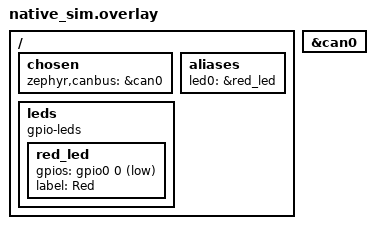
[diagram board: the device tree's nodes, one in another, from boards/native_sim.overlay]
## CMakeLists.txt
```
# SPDX-FileCopyrightText: Copyright (C) Frickly Systems GmbH
# SPDX-FileCopyrightText: Copyright (C) MBition GmbH
#
# SPDX-License-Identifier: Apache-2.0

cmake_minimum_required(VERSION 3.13.1)

find_package(Zephyr REQUIRED HINTS $ENV{ZEPHYR_BASE})
project(uds)

file(GLOB SRC_FILES src/*.c)
target_sources(app PRIVATE ${SRC_FILES})
```

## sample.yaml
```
# Copyright (C) Frickly Systems GmbH
# Copyright (C) MBition GmbH
#
# SPDX-License-Identifier: Apache-2.0

sample:
  name: uds example
common:
  build_only: true
  integration_platforms:
    - ardep
    # this does not work
    # - native_sim/native/64
    # - native_sim
tests:
  example.uds.default:
    sysbuild: true
```

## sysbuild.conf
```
SB_CONFIG_BOOT_LOGIC_UDS_FIRMWARE_LOADER=y
```

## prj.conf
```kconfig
CONFIG_CAN=y

CONFIG_UDS=y

CONFIG_LOG=y
CONFIG_LOG_INFO_COLOR_GREEN=y

CONFIG_HEAP_MEM_POOL_SIZE=1024
CONFIG_STD_C17=y

CONFIG_GPIO=y

# used for generating a seed for the security access function
CONFIG_TEST_RANDOM_GENERATOR=y 

# Enable filesystem support for UDS file transfer tests
CONFIG_FILE_SYSTEM=y
CONFIG_FILE_SYSTEM_LITTLEFS=y
CONFIG_FLASH_MAP=y
CONFIG_FLASH_PAGE_LAYOUT=y

# Enable mbedTLS for cryptographic functions in the  UDS authentication function
CONFIG_MBEDTLS=y
CONFIG_MBEDTLS_BUILTIN=y
# PSA Crypto API provider (authentication.c uses psa_* directly; the legacy
# mbedtls_aes_*/ctr_drbg_*/entropy_* API was removed from the public surface
# in Mbed TLS 4.x)
CONFIG_MBEDTLS_PSA_CRYPTO_C=y
# AES-128 ECB used by aes_encrypt_ecb()/aes_decrypt_ecb()
CONFIG_PSA_WANT_KEY_TYPE_AES=y
CONFIG_PSA_WANT_ALG_ECB_NO_PADDING=y
# DRBG + entropy back the PSA RNG used by psa_generate_random()
CONFIG_MBEDTLS_CTR_DRBG_C=y
CONFIG_MBEDTLS_ENTROPY_C=y

# mbedtls needs more stack
CONFIG_ISO14229_THREAD_STACK_SIZE=4096
```

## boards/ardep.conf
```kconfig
CONFIG_UDS_USE_LINK_CONTROL=y
```

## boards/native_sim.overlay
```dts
/*
 * SPDX-FileCopyrightText: Copyright (C) Frickly Systems GmbH
 * SPDX-FileCopyrightText: Copyright (C) MBition GmbH
 *
 * SPDX-License-Identifier: Apache-2.0
 */

/ {
    chosen {
        zephyr,canbus = &can0;
    };

    aliases {
		led0 = &red_led;
    };

	leds {
		compatible = "gpio-leds";

		red_led: red_led {
            gpios = <&gpio0 0 GPIO_ACTIVE_LOW>;
			label = "Red";
		};
	};
};

&can0 {
    status = "okay";
};
```

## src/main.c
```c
/*
 * SPDX-FileCopyrightText: Copyright (C) Frickly Systems GmbH
 * SPDX-FileCopyrightText: Copyright (C) MBition GmbH
 *
 * SPDX-License-Identifier: Apache-2.0
 */

#include <zephyr/logging/log.h>
LOG_MODULE_REGISTER(uds_sample, LOG_LEVEL_DBG);

#include "uds.h"

#include <zephyr/drivers/can.h>
#include <zephyr/kernel.h>

#include <ardep/iso14229.h>
#include <ardep/uds.h>

static const struct device *can_dev = DEVICE_DT_GET(DT_CHOSEN(zephyr_canbus));

struct uds_instance_t instance;

UDS_REGISTER_ECU_DEFAULT_HARD_RESET_HANDLER(&instance);

int mount_fs(void) { return 0; }

int main(void) {
  int err;
  LOG_INF("ARDEP UDS Sample");

  err = mount_fs();
  if (err) {
    LOG_ERR("Failed to mount filesystem: %d", err);
    return err;
  }

  UDSISOTpCConfig_t cfg = {
    // Hardware Addresses
    .source_addr = 0x7E8,
    .target_addr = 0x7E0,

    // Functional Addresses
    .source_addr_func = 0x7DF,
    .target_addr_func = UDS_TP_NOOP_ADDR,
  };

  uds_init(&instance, &cfg, can_dev, &auth_data);

  if (!device_is_ready(can_dev)) {
    LOG_INF("CAN device not ready");
    return -ENODEV;
  }

  err = can_set_mode(can_dev, CAN_MODE_NORMAL);
  if (err) {
    LOG_ERR("Failed to set CAN mode: %d", err);
    return err;
  }

  err = can_start(can_dev);
  if (err) {
    LOG_ERR(
        "Failed to start CAN device: "
        "%d",
        err);
    return err;
  }
  LOG_INF("CAN device started");

  instance.iso14229.thread_start(&instance.iso14229);
  LOG_INF("UDS thread started");
}

#ifdef CONFIG_UDS_USE_LINK_CONTROL

UDS_REGISTER_LINK_CONTROL_DEFAULT_HANDLER(&instance);

#endif  // CONFIG_UDS_USE_LINK_CONTROL
```

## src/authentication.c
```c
/*
 * SPDX-FileCopyrightText: Copyright (C) Frickly Systems GmbH
 * SPDX-FileCopyrightText: Copyright (C) MBition GmbH
 *
 * SPDX-License-Identifier: Apache-2.0
 */

#include <zephyr/logging/log.h>
LOG_MODULE_DECLARE(uds_sample, LOG_LEVEL_DBG);

#include "iso14229.h"
#include "uds.h"

#include <zephyr/kernel.h>

#include <ardep/uds.h>
#include <psa/crypto.h>

const unsigned char uds_aes_key_bin[] = {0xc3, 0x6a, 0xd3, 0x5c, 0xa2, 0xb7,
                                         0x0e, 0x82, 0xf7, 0xc3, 0x7a, 0xfa,
                                         0x62, 0xad, 0xae, 0xc2};
static const unsigned char *const uds_aes_key = uds_aes_key_bin;

struct authentication_data auth_data = {
  // Whether we are authenticated or not
  .authenticated = false,
  // Current seed we send to the client
  .seeed = {0},
  // BER encoded OID for AES-128 CBC (OID 2.16.840.1.101.3.4.1.2)
  // https://oidref.com/2.16.840.1.101.3.4.1.2
  .algorithm_authenticator = {0x06, 0x09, 0x60, 0x86, 0x48, 0x01, 0x65, 0x03,
                              0x04, 0x01, 0x02, 0x00, 0x00, 0x00, 0x00, 0x00},
};

// AES-128 single-block ECB via the PSA Crypto API. The legacy mbedtls_aes_*
// low-level API was removed from the public surface in Mbed TLS 4.x.
static int aes_ecb_crypt(const uint8_t *key, const uint8_t *input,
                         uint8_t *output, bool encrypt) {
  psa_key_attributes_t attr = PSA_KEY_ATTRIBUTES_INIT;
  psa_key_id_t key_id;
  psa_status_t status;
  size_t output_len;

  if (psa_crypto_init() != PSA_SUCCESS) {
    return -1;
  }

  psa_set_key_usage_flags(
      &attr, encrypt ? PSA_KEY_USAGE_ENCRYPT : PSA_KEY_USAGE_DECRYPT);
  psa_set_key_algorithm(&attr, PSA_ALG_ECB_NO_PADDING);
  psa_set_key_type(&attr, PSA_KEY_TYPE_AES);
  psa_set_key_bits(&attr, 128);

  status = psa_import_key(&attr, key, 16, &key_id);
  if (status != PSA_SUCCESS) {
    return -1;
  }

  if (encrypt) {
    status = psa_cipher_encrypt(key_id, PSA_ALG_ECB_NO_PADDING, input, 16,
                                output, 16, &output_len);
  } else {
    status = psa_cipher_decrypt(key_id, PSA_ALG_ECB_NO_PADDING, input, 16,
                                output, 16, &output_len);
  }

  psa_destroy_key(key_id);

  return (status == PSA_SUCCESS && output_len == 16) ? 0 : -1;
}

int aes_encrypt_ecb(const uint8_t *key, const uint8_t *input, uint8_t *output) {
  return aes_ecb_crypt(key, input, output, true);
}

int aes_decrypt_ecb(const uint8_t *key, const uint8_t *input, uint8_t *output) {
  return aes_ecb_crypt(key, input, output, false);
}

int generate_random_seed(uint8_t *seed) {
  if (psa_crypto_init() != PSA_SUCCESS) {
    return -1;
  }

  return (psa_generate_random(seed, 16) == PSA_SUCCESS) ? 0 : -1;
}

static UDSErr_t auth_check(const struct uds_context *const context,
                           bool *apply_action) {
  *apply_action = true;
  return UDS_OK;
}

static UDSErr_t auth_action(struct uds_context *const context,
                            bool *consume_event) {
  UDSAuthArgs_t *args = context->arg;
  struct authentication_data *auth = context->registration->auth.user_context;

  switch (args->type) {
    case UDS_LEV_AT_RCFA: {  // requestChallengeForAuthentication (0x05)
      LOG_INF("Authentication request received");

      if (memcmp(args->subFuncArgs.reqChallengeArgs.algoInd,
                 auth->algorithm_authenticator, 16) != 0) {
        LOG_ERR("Unsupported algorithm indicator");
        return UDS_NRC_ConditionsNotCorrect;
      }

      if (generate_random_seed(auth->seeed) != 0) {
        LOG_ERR("Failed to generate random seed");
        return UDS_NRC_GeneralReject;
      }

      LOG_HEXDUMP_INF(auth->seeed, 16, "Generated seed");

      uint8_t seed_len[] = {0x00, 0x10};  // 16 bytes
      args->copy(context->server, seed_len, sizeof(seed_len));
      args->copy(context->server, auth->seeed, sizeof(auth->seeed));

      uint8_t additional_param_len[] = {0x00, 0x00};
      args->copy(context->server, additional_param_len,
                 sizeof(additional_param_len));

      return args->set_auth_state(context->server, UDS_AT_RA);
    }
    case UDS_LEV_AT_VPOWNU: {  // verifyProofOfOwnershipUnidirectional (0x06)
      LOG_INF("Verify Proof Of Ownership Unidirectional");

      if (memcmp(args->subFuncArgs.verifyPownArgs.algoInd,
                 auth->algorithm_authenticator, 16) != 0) {
        LOG_ERR("Unsupported algorithm indicator\n");
        return UDS_NRC_ConditionsNotCorrect;
      }

      // Extract proof of ownership (encrypted seed)
      if (args->subFuncArgs.verifyPownArgs.pownLen != 16) {
        LOG_ERR("Invalid proof of ownership length: %d (expected 16)",
                args->subFuncArgs.verifyPownArgs.pownLen);
        return UDS_NRC_IncorrectMessageLengthOrInvalidFormat;
      }

      uint8_t *encrypted_proof =
          (uint8_t *)args->subFuncArgs.verifyPownArgs.pown;
      LOG_HEXDUMP_INF(encrypted_proof, 16, "Received encrypted proof:");

      // Decrypt the proof using our AES key
      uint8_t decrypted_proof[16];
      if (aes_decrypt_ecb(uds_aes_key, encrypted_proof, decrypted_proof) != 0) {
        LOG_ERR("Failed to decrypt proof of ownership");
        return UDS_NRC_GeneralReject;
      }

      LOG_HEXDUMP_INF(decrypted_proof, 16, "Decrypted proof:");
      LOG_HEXDUMP_INF(auth->seeed, 16, "Expected seed:");

      // Compare decrypted proof with the seed we sent
      if (memcmp(decrypted_proof, auth->seeed, 16) != 0) {
        LOG_ERR(
            "Proof verification failed - decrypted proof does not match "
            "seed\n");
        auth->authenticated = false;
        return UDS_NRC_InvalidKey;
      }

      LOG_INF("Proof verification successful! Client is now authenticated.");
      auth->authenticated = true;

      uint8_t session_key_len[] = {0x00, 0x00};
      args->copy(context->server, session_key_len, sizeof(session_key_len));
      return args->set_auth_state(context->server, UDS_AT_OVAC);
    }
    case UDS_LEV_AT_DA: {  // deAuthenticate (0x00)
      LOG_INF("De-authenticate request");
      auth->authenticated = false;

      UDSErr_t ret = args->set_auth_state(context->server, UDS_AT_DAS);
      if (ret != UDS_OK) {
        LOG_INF("Failed to copy de-authentication response");
        return ret;
      }

      return UDS_OK;
    }
    default:
      return UDS_NRC_SubFunctionNotSupported;
  }
}

static UDSErr_t auth_timeout_check(const struct uds_context *const context,
                                   bool *apply_action) {
  *apply_action = true;
  return UDS_OK;
}

static UDSErr_t auth_timeout_action(struct uds_context *const context,
                                    bool *consume_event) {
  struct authentication_data *auth = context->registration->auth.user_context;
  auth->authenticated = false;

  LOG_INF("Authentication timeout - user de-authenticated");

  *consume_event = true;
  return UDS_PositiveResponse;
}

UDS_REGISTER_AUTHENTICATION_HANDLER(&uds_default_instance,
                                    auth_check,
                                    auth_action,
                                    auth_timeout_check,
                                    auth_timeout_action,
                                    &auth_data);
```

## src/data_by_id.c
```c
/*
 * SPDX-FileCopyrightText: Copyright (C) Frickly Systems GmbH
 * SPDX-FileCopyrightText: Copyright (C) MBition GmbH
 *
 * SPDX-License-Identifier: Apache-2.0
 */

#include "iso14229.h"

#include <zephyr/logging/log.h>
LOG_MODULE_DECLARE(uds_sample, LOG_LEVEL_DBG);

#include "uds.h"

#include <zephyr/drivers/gpio.h>
#include <zephyr/kernel.h>
#include <zephyr/sys/byteorder.h>

// Setup data for Data by Identifier handlers
const uint16_t primitive_type_id = 0x50;
uint16_t primitive_type = 5;
uint16_t primitive_type_size = sizeof(primitive_type);

const uint16_t string_id = 0x100;
char string[] = "Hello from UDS";
// Include NULL as string terminator
uint16_t string_size = sizeof(string);

const uint16_t authenticated_type_id = 0x150;
uint8_t authenticated_type = 0x42;
uint16_t authenticated_type_size = sizeof(authenticated_type);

// Check function for the Read Data by Identifier event
// This callback is used for all data identifiers defined above. Because of
// this, we need to check for the dataID in here. Otherwise, we can assume the
// correct data ID because it is checked by the framework
UDSErr_t read_data_by_id_check(const struct uds_context *const context,
                               bool *apply_action) {
  UDSRDBIArgs_t *args = context->arg;

  // Check for authentication if required
  if (args->dataId == authenticated_type_id) {
    struct authentication_data *auth = context->instance->user_context;
    if (!auth->authenticated) {
      LOG_WRN("Access to data id 0x%02X denied - client not authenticated",
              context->registration->data_identifier.data_id);
      // If we are not authenticated, we are not allowed to read this data
      // We return a NRC which gets propagated to the client.
      // No other event handlers are checked after this.
      return UDS_NRC_ConditionsNotCorrect;
    } else {
      LOG_INF("Access to data id 0x%02X granted - client authenticated",
              context->registration->data_identifier.data_id);
    }
  }

  LOG_INF("Check to read data id: 0x%02X successful",
          context->registration->data_identifier.data_id);

  // Set to true, when we want to handle this event
  *apply_action = true;
  return UDS_OK;
}

// Action function for the Read Data by Identifier event
// This callback is used for all data identifiers defined above. Because of
// this, we need to split our actions by dataID.
UDSErr_t read_data_by_id_action(struct uds_context *const context,
                                bool *consume_event) {
  UDSRDBIArgs_t *args = context->arg;

  LOG_INF("Reading data id: 0x%02X", args->dataId);

  uint8_t temp[50] = {0};

  uint16_t size =
      *(uint16_t *)context->registration->data_identifier.user_context;

  if (args->dataId == primitive_type_id) {
    // Convert to MSB-First as defined in the ISO 14229 standard
    uint16_t t = sys_cpu_to_be16(
        *(uint16_t *)context->registration->data_identifier.data);
    memcpy(temp, &t, sizeof(t));
  } else if (args->dataId == string_id ||
             args->dataId == authenticated_type_id) {
    // Transport string or raw data unchanged as raw data without conversion
    memcpy(temp, context->registration->data_identifier.data, size);
  }

  // Signal this action consumes the event
  *consume_event = true;

  // Copy the data into the response buffer
  return args->copy(context->server, temp, size);
}

// Check function for the Write Data by Identifier event
UDSErr_t write_primitive_data_by_id_check(
    const struct uds_context *const context, bool *apply_action) {
  // We don't need any additional checks here, so we can just set `apply_action`
  // and return

  LOG_INF("Check to write data id: 0x%02X successful",
          context->registration->data_identifier.data_id);
  *apply_action = true;
  return UDS_OK;
}

// Write function for the Write Data by Identifier event
UDSErr_t write_primitive_data_by_id_action(struct uds_context *const context,
                                           bool *consume_event) {
  UDSWDBIArgs_t *args = context->arg;

  // Convert the data from BE to CPU order
  uint16_t *data = context->registration->data_identifier.data;
  *data = sys_be16_to_cpu(*(uint16_t *)args->data);

  LOG_INF("Written data to id 0x%02X: 0x%04X",
          context->registration->data_identifier.data_id, *data);

  // Signal this action consumes the event
  *consume_event = true;

  return UDS_PositiveResponse;
}

// Register the data identifiers defined above
UDS_REGISTER_DATA_BY_IDENTIFIER_HANDLER(
    // UDS instance the event handler is registered for
    &instance,
    // Data Identifier of the data
    primitive_type_id,
    // Pointer to the data
    &primitive_type,
    // check and action functions to read and write the data
    read_data_by_id_check,
    read_data_by_id_action,
    write_primitive_data_by_id_check,
    write_primitive_data_by_id_action,
    // IO Control check and action functions (unsused and therefore set to NULL)
    NULL,
    NULL,
    // User context pointer (used to store the size of the data here)
    &primitive_type_size);

UDS_REGISTER_DATA_BY_IDENTIFIER_HANDLER(&instance,
                                        string_id,
                                        &string,
                                        read_data_by_id_check,
                                        read_data_by_id_action,
                                        NULL,
                                        NULL,
                                        NULL,
                                        NULL,
                                        &string_size);

UDS_REGISTER_DATA_BY_IDENTIFIER_HANDLER(&instance,
                                        authenticated_type_id,
                                        &authenticated_type,
                                        read_data_by_id_check,
                                        read_data_by_id_action,
                                        NULL,
                                        NULL,
                                        NULL,
                                        NULL,
                                        &authenticated_type_size);

#define LED0_NODE DT_ALIAS(led0)

static const struct gpio_dt_spec led = GPIO_DT_SPEC_GET(LED0_NODE, gpios);

K_MUTEX_DEFINE(led_data_mutex);

const uint16_t led_id = 0x200;
struct {
  // LED state as set by the WriteDataByIdentifier service
  uint8_t led_state;
  // LED state override from io_control
  uint8_t io_control_led_state;
  // Whether IO Control is active or not
  bool io_control_active;
} led_data;

UDSErr_t read_led_check(const struct uds_context *const context,
                        bool *apply_action) {
  // We don't need any additional checks here, so we can just set `apply_action`
  // and return

  LOG_INF("Check to read led state");
  *apply_action = true;
  return UDS_OK;
}

UDSErr_t read_led_action(struct uds_context *const context,
                         bool *consume_event) {
  int led_state = gpio_pin_get_dt(&led);
  if (led_state < 0) {
    LOG_ERR("Failed to read LED state");
    // Return an error if something goes wrong during the handling of the event
    return UDS_NRC_ConditionsNotCorrect;
  }
  LOG_INF("Reading led state: 0x%02X", led_state);

  UDSRDBIArgs_t *args = context->arg;
  uint8_t state = (uint8_t)led_state;

  *consume_event = true;
  return args->copy(context->server, &state, sizeof(state));
}

UDSErr_t write_led_check(const struct uds_context *const context,
                         bool *apply_action) {
  // We don't need any additional checks here, so we can just set `apply_action`
  // and return

  LOG_INF("Check to update led state");
  *apply_action = true;
  return UDS_OK;
}

UDSErr_t write_led_action(struct uds_context *const context,
                          bool *consume_event) {
  UDSWDBIArgs_t *args = context->arg;
  if (args->len < 1) {
    LOG_ERR("Invalid data length for LED state");
    return UDS_NRC_IncorrectMessageLengthOrInvalidFormat;
  }

  uint8_t new_led_state = args->data[0];

  k_mutex_lock(&led_data_mutex, K_FOREVER);
  // We set the led state here, but it will not get applied if we disabled
  // updates via IOControl
  led_data.led_state = new_led_state;
  k_mutex_unlock(&led_data_mutex);

  LOG_INF("Updated LED state: 0x%02X", new_led_state);
  *consume_event = true;

  return UDS_PositiveResponse;
}

UDSErr_t io_ctrl_led_check(const struct uds_context *const context,
                           bool *apply_action) {
  LOG_INF("Check for LED IO control");
  *apply_action = true;
  return UDS_OK;
}

UDSErr_t io_ctrl_led_action(struct uds_context *const context,
                            bool *consume_event) {
  UDSIOCtrlArgs_t *args = context->arg;

  if (args->ioCtrlParam == UDS_IO_CONTROL__SHORT_TERM_ADJUSTMENT &&
      args->ctrlStateAndMaskLen >= 1) {
    k_mutex_lock(&led_data_mutex, K_FOREVER);
    int current_led_state = gpio_pin_get_dt(&led);
    if (current_led_state < 0) {
      k_mutex_unlock(&led_data_mutex);
      LOG_ERR("Failed to read LED state (IO control)");
      return UDS_NRC_ConditionsNotCorrect;
    }

    // Set IO Control active to notify the update thread to not apply received
    // updates anymore
    led_data.io_control_active = true;
    led_data.io_control_led_state = *(uint8_t *)args->ctrlStateAndMask;
    LOG_INF("Set LED state (IO control): 0x%02X",
            led_data.io_control_led_state);
    k_mutex_unlock(&led_data_mutex);

    uint8_t state = (uint8_t)current_led_state;
    return args->copy(context->server, &state, sizeof(state));
  } else if (args->ioCtrlParam == UDS_IO_CONTROL__RESET_TO_DEFAULT) {
    k_mutex_lock(&led_data_mutex, K_FOREVER);
    const uint8_t state = 0;
    // Reset to the default state (0) for both, 'actual' value and IO Control
    // override
    led_data.io_control_led_state = state;
    led_data.led_state = state;
    k_mutex_unlock(&led_data_mutex);

    return args->copy(context->server, &state, sizeof(state));
  }
  if (args->ioCtrlParam == UDS_IO_CONTROL__RETURN_CONTROL_TO_ECU) {
    k_mutex_lock(&led_data_mutex, K_FOREVER);
    // Disable IO Control, so that the update thread applies the last set
    // led_state again
    uint8_t state = led_data.led_state;
    led_data.io_control_active = false;
    k_mutex_unlock(&led_data_mutex);

    return args->copy(context->server, &state, sizeof(state));
  }

  return UDS_NRC_RequestOutOfRange;
}

UDS_REGISTER_DATA_BY_IDENTIFIER_HANDLER(&instance,
                                        led_id,
                                        &led_data.led_state,
                                        read_led_check,
                                        read_led_action,
                                        write_led_check,
                                        write_led_action,
                                        io_ctrl_led_check,
                                        io_ctrl_led_action,
                                        &led_data);

// Thread that periodically updates the LED state depending on the state and
// the override from IO Control
void led_update_thread(void *p1, void *p2, void *p3) {
  ARG_UNUSED(p1);
  ARG_UNUSED(p2);
  ARG_UNUSED(p3);

  k_mutex_lock(&led_data_mutex, K_FOREVER);
  int ret = gpio_pin_configure_dt(&led, GPIO_OUTPUT_ACTIVE);
  if (ret < 0) {
    LOG_ERR("Unable to configure led\n");
    return;
  }

  led_data.led_state = 0;
  led_data.io_control_active = false;
  led_data.io_control_led_state = 0;
  k_mutex_unlock(&led_data_mutex);

  while (true) {
    k_mutex_lock(&led_data_mutex, K_FOREVER);
    // If IO Control is active, we want to set the override state
    if (led_data.io_control_active) {
      gpio_pin_set_dt(&led, led_data.io_control_led_state);
    } else {
      gpio_pin_set_dt(&led, led_data.led_state);
    }
    k_mutex_unlock(&led_data_mutex);
    k_sleep(K_MSEC(100));
  }
}

K_THREAD_DEFINE(led_update_thread_id,
                512,
                led_update_thread,
                NULL,
                NULL,
                NULL,
                K_PRIO_PREEMPT(7),
                0,
                0);
```

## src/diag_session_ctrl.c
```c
/*
 * SPDX-FileCopyrightText: Copyright (C) Frickly Systems GmbH
 * SPDX-FileCopyrightText: Copyright (C) MBition GmbH
 *
 * SPDX-License-Identifier: Apache-2.0
 */

#include <zephyr/logging/log.h>
LOG_MODULE_DECLARE(uds_sample, LOG_LEVEL_DBG);

#include "uds.h"

#include <zephyr/retention/bootmode.h>
#include <zephyr/retention/retention.h>
#include <zephyr/sys/reboot.h>

#include <ardep/uds.h>

const struct device* retention_data =
    DEVICE_DT_GET(DT_CHOSEN(zephyr_firmware_loader_args));

// Check function for the Diagnostic Session Control event
UDSErr_t diag_session_ctrl_check(const struct uds_context* const context,
                                 bool* apply_action) {
  // Type the argument object
  // We don't need to check, that the event matches. This is done internally by
  // the UDS lib
  UDSDiagSessCtrlArgs_t* args = context->arg;

  // Set to true, if the action should be applied.
  // Here you can check other conditions if needed
  *apply_action = true;
  LOG_INF("Check to change diagnostic session to 0x%02X successful",
          args->type);

  // Return `UDS_OK` if everything is fine, or an NRC to abort event handling
  // and return this error code to the client
  return UDS_OK;
}

// Action function for the Diagnostic Session Control event
UDSErr_t diag_session_ctrl_action(struct uds_context* const context,
                                  bool* consume_event) {
  UDSDiagSessCtrlArgs_t* args = context->arg;

  if (args->type == UDS_DIAG_SESSION__PROGRAMMING) {
    LOG_INF("Switching into firmware loader");
    return uds_switch_to_firmware_loader_with_programming_session();
  }

  LOG_INF("Changing diagnostic session to 0x%02X", args->type);

  // We don't want to consume the event here, because the LinkControl handler
  // must know about it so it can reset the bitrate to its default value
  // If there are no other event handlers that would need the event, you can
  // stop iteration over other event handlers by setting `*consume_event =
  // true;`
  *consume_event = false;

  // Return the response code that the service should return to the client
  return UDS_PositiveResponse;
}

// Check function for the Diagnostic Session Timeout event
// This event is generated independent of the client and emitted when the
// Session timeout is reached
UDSErr_t diag_session_timeout_check(const struct uds_context* const context,
                                    bool* apply_action) {
  *apply_action = true;
  LOG_INF("Check to act on Diagnostic Session Timeout successful");
  return UDS_OK;
}

// Action function for the Diagnostic Session Timeout event
UDSErr_t diag_session_timeout_action(struct uds_context* const context,
                                     bool* consume_event) {
  LOG_INF("Diagnostic Session Timeout handled");

  // We don't want to consume the event here, because the LinkControl handler
  // must know about it so it can reset the bitrate to its default value
  *consume_event = false;

  // As this is not tied to a client request, nothing will be returned to the
  // client. This just signals the unterlying server whether the event was
  // handled successfully.
  return UDS_PositiveResponse;
}

// Registration Macro to register the event handlers we defined above
UDS_REGISTER_DIAG_SESSION_CTRL_HANDLER(
    // The UDS instance we want to register
    // the handler for
    &instance,
    // Check and Action functions for the events
    diag_session_ctrl_check,
    diag_session_ctrl_action,
    diag_session_timeout_check,
    diag_session_timeout_action,
    // Optional user context pointer that is passed wit the context to every
    // handler
    NULL)
```

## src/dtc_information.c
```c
/*
 * SPDX-FileCopyrightText: Copyright (C) Frickly Systems GmbH
 * SPDX-FileCopyrightText: Copyright (C) MBition GmbH
 *
 * SPDX-License-Identifier: Apache-2.0
 */

#include <zephyr/logging/log.h>
LOG_MODULE_DECLARE(uds_sample, LOG_LEVEL_DBG);

#include "ardep/iso14229.h"
#include "ardep/uds.h"
#include "uds.h"

#include <zephyr/kernel.h>

K_MUTEX_DEFINE(dtc_record_mutex);

struct DtcRecord {
  uint8_t dtc[3];
  uint8_t status;
  bool is_active;
  bool is_frozen;
};

const uint8_t dtc_status_availability_mask = 0x7F;
struct DtcRecord dtc_records[] = {
  {.dtc = {0x0A, 0x9B, 0x17},
   .status = 0x24,
   .is_active = true,
   .is_frozen = false},
  {.dtc = {0x80, 0x51, 0x11},
   .status = 0x2F,
   .is_active = true,
   .is_frozen = false},
};

UDSErr_t read_dtc_info_check(const struct uds_context *const context,
                             bool *apply_action) {
  UDSRDTCIArgs_t *args = context->arg;

  // We don't need to filter/check the subfunction ID as this is checked
  // internally before calling this function.

  LOG_INF("Reading DT information by status mask: 0x%02X",
          args->subFuncArgs.numOfDTCByStatusMaskArgs.mask);

  *apply_action = true;
  return UDS_OK;
}

UDSErr_t read_dtc_info_action(struct uds_context *const context,
                              bool *consume_event) {
  UDSRDTCIArgs_t *args = context->arg;

  int ret = args->copy(context->server, &dtc_status_availability_mask,
                       sizeof(dtc_status_availability_mask));
  if (ret != UDS_OK) {
    LOG_ERR("Failed to copy DTC status availability mask: %d", ret);
    return ret;
  }

  k_mutex_lock(&dtc_record_mutex, K_FOREVER);
  for (uint32_t i = 0; i < ARRAY_SIZE(dtc_records); i++) {
    if (dtc_records[i].status &
            args->subFuncArgs.numOfDTCByStatusMaskArgs.mask &&
        dtc_records[i].is_active) {
      ret = args->copy(context->server, dtc_records[i].dtc,
                       sizeof(dtc_records[i].dtc));
      if (ret != UDS_OK) {
        uint32_t dtc_value = (dtc_records[i].dtc[0] << 16) |
                             (dtc_records[i].dtc[1] << 8) |
                             dtc_records[i].dtc[2];
        LOG_ERR("Failed to copy DTC: 0x%06X ; Err = %d", dtc_value, ret);
        k_mutex_unlock(&dtc_record_mutex);
        return ret;
      }
      ret = args->copy(context->server, &dtc_records[i].status,
                       sizeof(dtc_records[i].status));
      if (ret != UDS_OK) {
        uint32_t dtc_value = (dtc_records[i].dtc[0] << 16) |
                             (dtc_records[i].dtc[1] << 8) |
                             dtc_records[i].dtc[2];
        LOG_ERR("Failed to copy DTC status: 0x%06X (status: 0x%02X) ; Err = %d",
                dtc_value, dtc_records[i].status, ret);
        k_mutex_unlock(&dtc_record_mutex);
        return ret;
      }
    }
  }

  k_mutex_unlock(&dtc_record_mutex);

  *consume_event = true;
  return UDS_PositiveResponse;
}

UDS_REGISTER_READ_DTC_INFO_HANDLER(
    &instance,
    read_dtc_info_check,
    read_dtc_info_action,
    UDS_READ_DTC_INFO_SUBFUNC__DTC_BY_STATUS_MASK,
    NULL)

static void dtc_reactivate_work_handler(struct k_work *work) {
  k_mutex_lock(&dtc_record_mutex, K_FOREVER);
  for (uint32_t i = 0; i < ARRAY_SIZE(dtc_records); i++) {
    dtc_records[i].is_active = true;
  }
  k_mutex_unlock(&dtc_record_mutex);

  LOG_DBG("DTCs reactivated after clear operation");
}

K_WORK_DELAYABLE_DEFINE(dtc_reactivate_work, dtc_reactivate_work_handler);

UDSErr_t clear_diag_info_check(const struct uds_context *const context,
                               bool *apply_action) {
  UDSCDIArgs_t *args = context->arg;

  LOG_INF("Clearing Diagnostic information with group of DTC: 0x%06X",
          args->groupOfDTC);

  *apply_action = true;
  return UDS_OK;
}

UDSErr_t clear_diag_info_act(struct uds_context *const context,
                             bool *consume_event) {
  k_mutex_lock(&dtc_record_mutex, K_FOREVER);
  for (uint32_t i = 0; i < ARRAY_SIZE(dtc_records); i++) {
    dtc_records[i].is_active = false;
  }
  k_mutex_unlock(&dtc_record_mutex);

  // Schedule work to reactivate DTCs after 1 second
  if (k_work_delayable_is_pending(&dtc_reactivate_work)) {
    k_work_cancel_delayable(&dtc_reactivate_work);
  }
  k_work_schedule(&dtc_reactivate_work, K_SECONDS(1));

  *consume_event = true;
  return UDS_PositiveResponse;
}

UDS_REGISTER_CLEAR_DIAG_INFO_HANDLER(&instance,
                                     clear_diag_info_check,
                                     clear_diag_info_act,
                                     NULL)

// Control DTC Setting handlers
UDSErr_t control_dtc_setting_check(const struct uds_context *const context,
                                   bool *apply_action) {
  UDSControlDTCSettingArgs_t *args = context->arg;

  LOG_INF("Control DTC Setting request - Type: 0x%02X, Length: %u", args->type,
          args->len);

  *apply_action = true;
  return UDS_OK;
}

UDSErr_t control_dtc_setting_action(struct uds_context *const context,
                                    bool *consume_event) {
  UDSControlDTCSettingArgs_t *args = context->arg;

  k_mutex_lock(&dtc_record_mutex, K_FOREVER);

  switch (args->type) {
    case 0x01:  // DTCSettingOn - Resume DTC status updates
      LOG_INF("DTC Setting ON - Resuming DTC status updates");
      for (uint32_t i = 0; i < ARRAY_SIZE(dtc_records); i++) {
        dtc_records[i].is_frozen = false;
      }
      break;

    case 0x02:  // DTCSettingOff - Freeze DTC status updates
      LOG_INF("DTC Setting OFF - Freezing DTC status updates");
      for (uint32_t i = 0; i < ARRAY_SIZE(dtc_records); i++) {
        dtc_records[i].is_frozen = true;
      }
      break;

    default:
      k_mutex_unlock(&dtc_record_mutex);
      LOG_WRN("Unsupported DTC Setting type: 0x%02X", args->type);
      *consume_event = false;
      return UDS_NRC_SubFunctionNotSupported;
  }

  k_mutex_unlock(&dtc_record_mutex);

  *consume_event = true;
  return UDS_PositiveResponse;
}

UDS_REGISTER_CONTROL_DTC_SETTING_HANDLER(&instance,
                                         control_dtc_setting_check,
                                         control_dtc_setting_action,
                                         NULL)

// Forward declaration for DTC status increment work
static void dtc_status_increment_work_handler(struct k_work *work);
K_WORK_DELAYABLE_DEFINE(dtc_status_increment_work,
                        dtc_status_increment_work_handler);

// DTC Status increment worker - runs every 50ms
static void dtc_status_increment_work_handler(struct k_work *work) {
  k_mutex_lock(&dtc_record_mutex, K_FOREVER);

  for (uint32_t i = 0; i < ARRAY_SIZE(dtc_records); i++) {
    if (!dtc_records[i].is_frozen) {
      dtc_records[i].status = (dtc_records[i].status + 1) & 0xFF;
    }
  }

  k_mutex_unlock(&dtc_record_mutex);

  // Reschedule for next increment
  k_work_schedule(&dtc_status_increment_work, K_MSEC(50));
}

// Initialize the DTC status increment worker
static int dtc_status_init(void) {
  LOG_INF("Starting DTC status increment worker (50ms interval)");
  k_work_schedule(&dtc_status_increment_work, K_MSEC(50));
  return 0;
}

SYS_INIT(dtc_status_init, APPLICATION, CONFIG_APPLICATION_INIT_PRIORITY);
```

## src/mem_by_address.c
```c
/*
 * SPDX-FileCopyrightText: Copyright (C) Frickly Systems GmbH
 * SPDX-FileCopyrightText: Copyright (C) MBition GmbH
 *
 * SPDX-License-Identifier: Apache-2.0
 */

#include <zephyr/logging/log.h>
LOG_MODULE_DECLARE(uds_sample, LOG_LEVEL_DBG);

#include "ardep/uds.h"
#include "iso14229.h"
#include "uds.h"

const uint32_t fake_memory_start_addr = 0x00001000;
uint8_t fake_memory[100] = {
  0x01, 0x02, 0x03, 0x04, 0x05, 0x05, 0x07, 0x08, 0x09, 0x0A, 0x0B, 0x0C, 0x0D,
  0x0E, 0x0F, 0x10, 0x11, 0x12, 0x13, 0x14, 0x15, 0x16, 0x17, 0x18, 0x19, 0x1A,
  0x1B, 0x1C, 0x1D, 0x1E, 0x1F, 0x20, 0x21, 0x22, 0x23, 0x24, 0x25, 0x26, 0x27,
  0x28, 0x29, 0x2A, 0x2B, 0x2C, 0x2D, 0x2E, 0x2F, 0x30, 0x31, 0x32, 0x33, 0x34,
  0x35, 0x36, 0x37, 0x38, 0x39, 0x3A, 0x3B, 0x3C, 0x3D, 0x3E, 0x3F, 0x40, 0x41,
  0x42, 0x43, 0x44, 0x45, 0x46, 0x47, 0x48, 0x49, 0x4A, 0x4B, 0x4C, 0x4D, 0x4E,
  0x4F, 0x50, 0x51, 0x52, 0x53, 0x54, 0x55, 0x56, 0x57, 0x58, 0x59, 0x5A, 0x5B,
  0x5C, 0x5D, 0x5E, 0x5F, 0x60, 0x61, 0x62, 0x63, 0x64};

UDSErr_t read_mem_by_address_check(const struct uds_context *const context,
                                   bool *apply_action) {
  UDSReadMemByAddrArgs_t *args = context->arg;
  uint32_t addr = (uint32_t)(uintptr_t)args->memAddr;
  uint32_t size = args->memSize;

  // Check if the address is within our fake memory range
  if (addr < fake_memory_start_addr ||
      (addr + size) >= (fake_memory_start_addr + sizeof(fake_memory))) {
    return UDS_OK;
  }

  *apply_action = true;
  LOG_INF("Check to read memory at address 0x%08X with size %d successful",
          addr, size);

  *apply_action = true;
  return UDS_OK;
}

UDSErr_t read_mem_by_address_action(struct uds_context *const context,
                                    bool *consume_event) {
  UDSReadMemByAddrArgs_t *args = context->arg;
  uint32_t addr = (uint32_t)(uintptr_t)args->memAddr;
  uint32_t size = args->memSize;

  LOG_INF("Reading memory at address 0x%08X with size %d", addr, size);

  return args->copy(context->server,
                    &fake_memory[addr - fake_memory_start_addr], size);
}

UDSErr_t write_mem_by_address_check(const struct uds_context *const context,
                                    bool *apply_action) {
  UDSWriteMemByAddrArgs_t *args = context->arg;
  uint32_t addr = (uint32_t)(uintptr_t)args->memAddr;
  uint32_t size = args->memSize;

  // Check if the address is within our fake memory range
  if (addr < fake_memory_start_addr ||
      (addr + size) >= (fake_memory_start_addr + sizeof(fake_memory))) {
    return UDS_OK;
  }

  *apply_action = true;
  LOG_INF("Check to write memory at address 0x%08X with size %d successful",
          addr, size);

  *apply_action = true;
  return UDS_OK;
}

UDSErr_t write_mem_by_address_action(struct uds_context *const context,
                                     bool *consume_event) {
  UDSWriteMemByAddrArgs_t *args = context->arg;
  uint32_t addr = (uint32_t)(uintptr_t)args->memAddr;
  uint32_t size = args->memSize;

  LOG_HEXDUMP_INF(args->data, size, "Writing to memory");

  memcpy(&fake_memory[addr - fake_memory_start_addr], args->data, size);

  return UDS_PositiveResponse;
}

UDS_REGISTER_MEMORY_HANDLER(&instance,
                            read_mem_by_address_check,
                            read_mem_by_address_action,
                            write_mem_by_address_check,
                            write_mem_by_address_action,
                            NULL)
```

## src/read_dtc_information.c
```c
/*
 * Copyright (C) Frickly Systems GmbH
 * Copyright (C) MBition GmbH
 *
 * SPDX-License-Identifier: Apache-2.0
 */

#include "ardep/uds.h"
#include "iso14229.h"

#include <zephyr/logging/log.h>
LOG_MODULE_DECLARE(uds_sample, LOG_LEVEL_DBG);

#include "uds.h"

struct DtcRecord {
  uint8_t dtc[3];
  uint8_t status;
};

const uint8_t dtc_status_availability_mask = 0x7F;
const struct DtcRecord dtc_records[] = {
  {.dtc = {0x0A, 0x9B, 0x17}, .status = 0x24},
  {.dtc = {0x80, 0x51, 0x11}, .status = 0x2F},
};

UDSErr_t read_dtc_info_check(const struct uds_context *const context,
                             bool *apply_action) {
  UDSRDTCIArgs_t *args = context->arg;

  // We don't need to filter/chck the subfunction ID as this is checked
  // internally before calling this function.

  LOG_INF("Reading DT information by status mask: 0x%02X",
          args->subFuncArgs.numOfDTCByStatusMaskArgs.mask);

  *apply_action = true;
  return UDS_OK;
}

UDSErr_t read_dtc_info_action(struct uds_context *const context,
                              bool *consume_event) {
  UDSRDTCIArgs_t *args = context->arg;

  int ret = args->copy(&context->instance->iso14229.server,
                       &dtc_status_availability_mask,
                       sizeof(dtc_status_availability_mask));
  if (ret != UDS_OK) {
    LOG_ERR("Failed to copy DTC status availability mask: %d", ret);
    return ret;
  }

  for (uint32_t i = 0; i < ARRAY_SIZE(dtc_records); i++) {
    if (dtc_records[i].status &
        args->subFuncArgs.numOfDTCByStatusMaskArgs.mask) {
      ret = args->copy(&context->instance->iso14229.server, dtc_records[i].dtc,
                       sizeof(dtc_records[i].dtc));
      if (ret != UDS_OK) {
        uint32_t dtc_value = (dtc_records[i].dtc[0] << 16) |
                             (dtc_records[i].dtc[1] << 8) |
                             dtc_records[i].dtc[2];
        LOG_ERR("Failed to copy DTC: 0x%06X ; Err = %d", dtc_value, ret);
        return ret;
      }
      ret = args->copy(&context->instance->iso14229.server,
                       &dtc_records[i].status, sizeof(dtc_records[i].status));
      if (ret != UDS_OK) {
        uint32_t dtc_value = (dtc_records[i].dtc[0] << 16) |
                             (dtc_records[i].dtc[1] << 8) |
                             dtc_records[i].dtc[2];
        LOG_ERR("Failed to copy DTC status: 0x%06X (status: 0x%02X) ; Err = %d",
                dtc_value, dtc_records[i].status, ret);
        return ret;
      }
    }
  }

  *consume_event = true;
  return UDS_PositiveResponse;
}

UDS_REGISTER_READ_DTC_INFO_HANDLER(
    &instance,
    read_dtc_info_check,
    read_dtc_info_action,
    UDS_READ_DTC_INFO_SUBFUNC__DTC_BY_STATUS_MASK,
    NULL)
```

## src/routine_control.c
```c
/*
 * SPDX-FileCopyrightText: Copyright (C) Frickly Systems GmbH
 * SPDX-FileCopyrightText: Copyright (C) MBition GmbH
 *
 * SPDX-License-Identifier: Apache-2.0
 */

#include <zephyr/logging/log.h>
LOG_MODULE_DECLARE(uds_sample, LOG_LEVEL_DBG);

#include "ardep/uds.h"
#include "uds.h"

#include <string.h>

#include <zephyr/kernel.h>
#include <zephyr/sys/byteorder.h>

#define SYNCHRONOUS_ROUTINE_ID 0x1234
#define ASYNCHRONOUS_ROUTINE_ID 0x5678

static UDSErr_t sync_routine_control_check(
    const struct uds_context *const context, bool *apply_action) {
  UDSRoutineCtrlArgs_t *args = context->arg;

  // We don't need to check the routine id, the framework already did that for
  // us

  if (args->len != 4) {
    // we operate on an uint32_t so we check the length of the status record
    return UDS_NRC_IncorrectMessageLengthOrInvalidFormat;
  }

  *apply_action = true;
  return UDS_OK;
}

static uint32_t sync_action(uint32_t input) {
  // Simulate some work
  k_msleep(30);
  return ~input;
}

static UDSErr_t sync_routine_control_action(struct uds_context *const context,
                                            bool *consume_event) {
  UDSRoutineCtrlArgs_t *args = context->arg;
  uint32_t input = sys_be32_to_cpu(*(uint32_t *)args->optionRecord);

  uint32_t output = sys_cpu_to_be32(sync_action(input));

  // Signal this action consumes the event
  *consume_event = true;

  return args->copyStatusRecord(context->server, &output, sizeof(output));
}

UDS_REGISTER_ROUTINE_CONTROL_HANDLER(&instance,
                                     SYNCHRONOUS_ROUTINE_ID,
                                     sync_routine_control_check,
                                     sync_routine_control_action,
                                     NULL)

enum async_work_status {
  ASYNC_WORK_STATUS_IDLE = 0,
  ASYNC_WORK_STATUS_SUCCESS = 1,
  ASYNC_WORK_STATUS_STOPPED = 2,
  ASYNC_WORK_STATUS_RUNNING = 3,
};

struct uds_async_work_data {
  uint32_t current_progress;
  enum async_work_status status;
  bool force_stop;
} async_work_data;

K_MUTEX_DEFINE(async_work_mutex);

void async_action(struct k_work *work) {
  k_mutex_lock(&async_work_mutex, K_FOREVER);
  if (async_work_data.status == ASYNC_WORK_STATUS_RUNNING) {
    // work is already running, so we do nothing
    k_mutex_unlock(&async_work_mutex);
    return;
  }

  async_work_data.status = ASYNC_WORK_STATUS_RUNNING;
  async_work_data.current_progress = 0;
  async_work_data.force_stop = false;
  k_mutex_unlock(&async_work_mutex);

  for (size_t i = 0; i < 3000; i++) {
    // Simulate some work
    k_msleep(1);
    k_mutex_lock(&async_work_mutex, K_FOREVER);
    if (async_work_data.force_stop) {
      async_work_data.status = ASYNC_WORK_STATUS_STOPPED;
      k_mutex_unlock(&async_work_mutex);
      return;
    }
    async_work_data.current_progress += 1;
    k_mutex_unlock(&async_work_mutex);
  }

  k_mutex_lock(&async_work_mutex, K_FOREVER);
  async_work_data.status = ASYNC_WORK_STATUS_SUCCESS;
  k_mutex_unlock(&async_work_mutex);
}

K_WORK_DELAYABLE_DEFINE(async_routine_work, async_action);

struct uds_async_routine_data {
  struct uds_async_work_data *work_data;
  struct k_work_delayable *work;
} async_routine_data = {
  .work_data = &async_work_data,
  .work = &async_routine_work,
};

static UDSErr_t async_routine_control_check(
    const struct uds_context *const context, bool *apply_action) {
  *apply_action = true;
  return UDS_OK;
}

static UDSErr_t async_routine_control_action(struct uds_context *const context,
                                             bool *consume_event) {
  UDSRoutineCtrlArgs_t *args = context->arg;
  struct uds_async_routine_data *data =
      context->registration->routine_control.user_context;

  *consume_event = true;

  switch (args->ctrlType) {
    case UDS_ROUTINE_CONTROL__START_ROUTINE: {
      // Check if work is already running
      if (k_work_delayable_is_pending(data->work)) {
        return UDS_NRC_RequestSequenceError;
      }

      // Check if work is already completed or stopped (should be idle to start)
      k_mutex_lock(&async_work_mutex, K_FOREVER);
      if (data->work_data->status == ASYNC_WORK_STATUS_RUNNING) {
        k_mutex_unlock(&async_work_mutex);
        return UDS_NRC_RequestSequenceError;
      }
      k_mutex_unlock(&async_work_mutex);

      // Schedule the work to start immediately
      int ret = k_work_schedule(data->work, K_NO_WAIT);
      if (ret < 0) {
        LOG_ERR("Failed to schedule async work: %d", ret);
        return UDS_NRC_ConditionsNotCorrect;
      }

      LOG_INF("Started async routine");

      // Return success status for start
      return UDS_PositiveResponse;
    }

    case UDS_ROUTINE_CONTROL__STOP_ROUTINE: {
      k_mutex_lock(&async_work_mutex, K_FOREVER);
      if (data->work_data->status != ASYNC_WORK_STATUS_RUNNING) {
        k_mutex_unlock(&async_work_mutex);
        return UDS_NRC_RequestSequenceError;
      }

      LOG_INF("Stopping async routine");

      // Signal the work to stop
      data->work_data->force_stop = true;
      k_mutex_unlock(&async_work_mutex);

      // Cancel pending work if still scheduled
      k_work_cancel_delayable(data->work);

      // Return stop acknowledgment
      uint8_t stop_status = ASYNC_WORK_STATUS_STOPPED;
      return args->copyStatusRecord(context->server, &stop_status,
                                    sizeof(stop_status));
    }

    case UDS_ROUTINE_CONTROL__REQUEST_ROUTINE_RESULTS: {
      k_mutex_lock(&async_work_mutex, K_FOREVER);
      LOG_INF("Sending async routine result");

      uint8_t output[5] = {0};
      output[0] = data->work_data->status;

      // Include progress data
      uint32_t progress_be = sys_cpu_to_be32(data->work_data->current_progress);
      memcpy(&output[1], &progress_be, sizeof(progress_be));

      k_mutex_unlock(&async_work_mutex);

      return args->copyStatusRecord(context->server, output, sizeof(output));
    }

    default:
      return UDS_NRC_SubFunctionNotSupported;
  }
}

UDS_REGISTER_ROUTINE_CONTROL_HANDLER(&instance,
                                     ASYNCHRONOUS_ROUTINE_ID,
                                     async_routine_control_check,
                                     async_routine_control_action,
                                     &async_routine_data)
```

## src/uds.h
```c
/*
 * SPDX-FileCopyrightText: Copyright (C) Frickly Systems GmbH
 * SPDX-FileCopyrightText: Copyright (C) MBition GmbH
 *
 * SPDX-License-Identifier: Apache-2.0
 */

#ifndef ARDEP_SAMPLES_UDS_SRC_UDS_H
#define ARDEP_SAMPLES_UDS_SRC_UDS_H

#include <ardep/uds.h>

extern struct uds_instance_t instance;

struct authentication_data {
  bool authenticated;
  uint8_t seeed[16];
  uint8_t algorithm_authenticator[16];
};

// Authentication data get assigned as the instance user context
extern struct authentication_data auth_data;

#endif  // ARDEP_SAMPLES_UDS_SRC_UDS_H
```
